AUTOSAR XML (schema 00046)
package /ComponentTypes
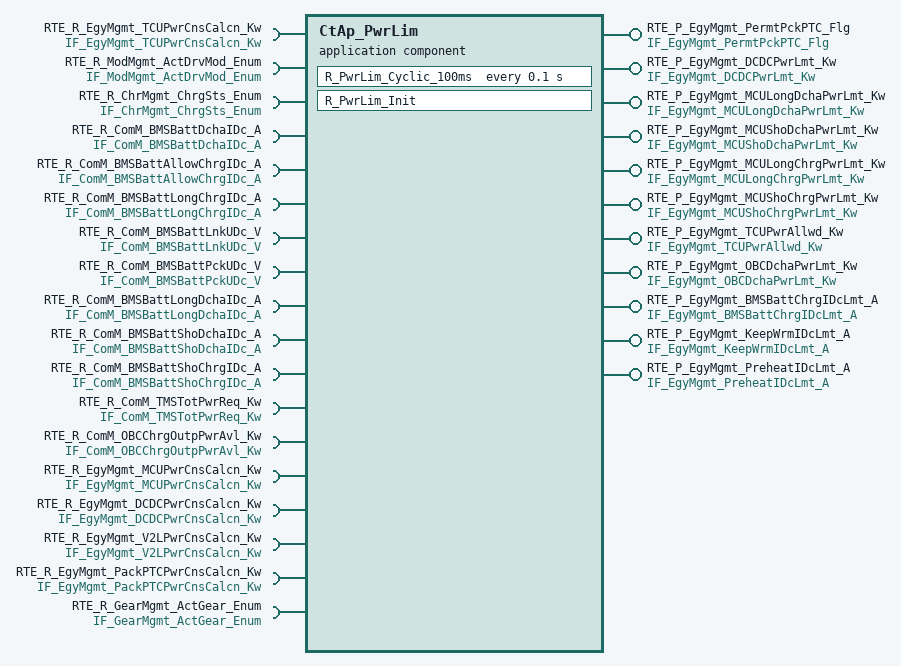
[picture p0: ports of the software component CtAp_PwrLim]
  application sw component type CtAp_PwrLim
    18 x require port:
      RTE_R_EgyMgmt_TCUPwrCnsCalcn_Kw: nonqueued-receiver-com-spec{data-element=tec_EgyMgmt_TCUPwrCnsCalcn_Kw, filter=data-filter-type=ALWAYS, init-value=0}, required-interface=IF_EgyMgmt_TCUPwrCnsCalcn_Kw
      RTE_R_ModMgmt_ActDrvMod_Enum: nonqueued-receiver-com-spec{data-element=tec_ModMgmt_ActDrvMod_Enum, filter=data-filter-type=ALWAYS, init-value=0}, required-interface=IF_ModMgmt_ActDrvMod_Enum
      RTE_R_ChrMgmt_ChrgSts_Enum: nonqueued-receiver-com-spec{data-element=tec_ChrMgmt_ChrgSts_Enum, filter=data-filter-type=ALWAYS, init-value=0}, required-interface=IF_ChrMgmt_ChrgSts_Enum
      RTE_R_ComM_BMSBattDchaIDc_A: nonqueued-receiver-com-spec{data-element=tec_ComM_BMSBattDchaIDc_A, filter=data-filter-type=ALWAYS, init-value=0}, required-interface=IF_ComM_BMSBattDchaIDc_A
      RTE_R_ComM_BMSBattAllowChrgIDc_A: nonqueued-receiver-com-spec{data-element=tec_ComM_BMSBattAllowChrgIDc_A, filter=data-filter-type=ALWAYS, init-value=0}, required-interface=IF_ComM_BMSBattAllowChrgIDc_A
      RTE_R_ComM_BMSBattLongChrgIDc_A: nonqueued-receiver-com-spec{data-element=tec_ComM_BMSBattLongChrgIDc_A, filter=data-filter-type=ALWAYS, init-value=0}, required-interface=IF_ComM_BMSBattLongChrgIDc_A
      RTE_R_ComM_BMSBattLnkUDc_V: nonqueued-receiver-com-spec{data-element=tec_ComM_BMSBattLnkUDc_V, filter=data-filter-type=ALWAYS, init-value=0}, required-interface=IF_ComM_BMSBattLnkUDc_V
      RTE_R_ComM_BMSBattPckUDc_V: nonqueued-receiver-com-spec{data-element=tec_ComM_BMSBattPckUDc_V, filter=data-filter-type=ALWAYS, init-value=0}, required-interface=IF_ComM_BMSBattPckUDc_V
      RTE_R_ComM_BMSBattLongDchaIDc_A: nonqueued-receiver-com-spec{data-element=tec_ComM_BMSBattLongDchaIDc_A, filter=data-filter-type=ALWAYS, init-value=0}, required-interface=IF_ComM_BMSBattLongDchaIDc_A
      RTE_R_ComM_BMSBattShoDchaIDc_A: nonqueued-receiver-com-spec{data-element=tec_ComM_BMSBattShoDchaIDc_A, filter=data-filter-type=ALWAYS, init-value=0}, required-interface=IF_ComM_BMSBattShoDchaIDc_A
      RTE_R_ComM_BMSBattShoChrgIDc_A: nonqueued-receiver-com-spec{data-element=tec_ComM_BMSBattShoChrgIDc_A, filter=data-filter-type=ALWAYS, init-value=0}, required-interface=IF_ComM_BMSBattShoChrgIDc_A
      RTE_R_ComM_TMSTotPwrReq_Kw: nonqueued-receiver-com-spec{data-element=tec_ComM_TMSTotPwrReq_Kw, filter=data-filter-type=ALWAYS, init-value=0}, required-interface=IF_ComM_TMSTotPwrReq_Kw
      RTE_R_ComM_OBCChrgOutpPwrAvl_Kw: nonqueued-receiver-com-spec{data-element=tec_ComM_OBCChrgOutpPwrAvl_Kw, filter=data-filter-type=ALWAYS, init-value=0}, required-interface=IF_ComM_OBCChrgOutpPwrAvl_Kw
      RTE_R_EgyMgmt_MCUPwrCnsCalcn_Kw: nonqueued-receiver-com-spec{data-element=tec_EgyMgmt_MCUPwrCnsCalcn_Kw, filter=data-filter-type=ALWAYS, init-value=0}, required-interface=IF_EgyMgmt_MCUPwrCnsCalcn_Kw
      RTE_R_EgyMgmt_DCDCPwrCnsCalcn_Kw: nonqueued-receiver-com-spec{data-element=tec_EgyMgmt_DCDCPwrCnsCalcn_Kw, filter=data-filter-type=ALWAYS, init-value=0}, required-interface=IF_EgyMgmt_DCDCPwrCnsCalcn_Kw
      RTE_R_EgyMgmt_V2LPwrCnsCalcn_Kw: nonqueued-receiver-com-spec{data-element=IF_EgyMgmt_V2LPwrCnsCalcn_Kw, filter=data-filter-type=ALWAYS, init-value=0}, required-interface=IF_EgyMgmt_V2LPwrCnsCalcn_Kw
      RTE_R_EgyMgmt_PackPTCPwrCnsCalcn_Kw: nonqueued-receiver-com-spec{data-element=tec_EgyMgmt_PackPTCPwrCnsCalcn_Kw, filter=data-filter-type=ALWAYS, init-value=0}, required-interface=IF_EgyMgmt_PackPTCPwrCnsCalcn_Kw
      RTE_R_GearMgmt_ActGear_Enum: nonqueued-receiver-com-spec{data-element=tec_GearMgmt_ActGear_Enum, filter=data-filter-type=ALWAYS, init-value=0}, required-interface=IF_GearMgmt_ActGear_Enum
    11 x provide port:
      RTE_P_EgyMgmt_PermtPckPTC_Flg: nonqueued-sender-com-spec{data-element=tec_EgyMgmt_PermtPckPTC_Flg, init-value=0}, provided-interface=IF_EgyMgmt_PermtPckPTC_Flg
      RTE_P_EgyMgmt_DCDCPwrLmt_Kw: nonqueued-sender-com-spec{data-element=tec_EgyMgmt_DCDCPwrLmt_Kw, init-value=0}, provided-interface=IF_EgyMgmt_DCDCPwrLmt_Kw
      RTE_P_EgyMgmt_MCULongDchaPwrLmt_Kw: nonqueued-sender-com-spec{data-element=tec_EgyMgmt_MCULongDchaPwrLmt_Kw, init-value=0}, provided-interface=IF_EgyMgmt_MCULongDchaPwrLmt_Kw
      RTE_P_EgyMgmt_MCUShoDchaPwrLmt_Kw: nonqueued-sender-com-spec{data-element=tec_EgyMgmt_MCUShoDchaPwrLmt_Kw, init-value=0}, provided-interface=IF_EgyMgmt_MCUShoDchaPwrLmt_Kw
      RTE_P_EgyMgmt_MCULongChrgPwrLmt_Kw: nonqueued-sender-com-spec{data-element=tec_EgyMgmt_MCULongChrgPwrLmt_Kw, init-value=0}, provided-interface=IF_EgyMgmt_MCULongChrgPwrLmt_Kw
      RTE_P_EgyMgmt_MCUShoChrgPwrLmt_Kw: nonqueued-sender-com-spec{data-element=tec_EgyMgmt_MCUShoChrgPwrLmt_Kw, init-value=0}, provided-interface=IF_EgyMgmt_MCUShoChrgPwrLmt_Kw
      RTE_P_EgyMgmt_TCUPwrAllwd_Kw: nonqueued-sender-com-spec{data-element=tec_EgyMgmt_TCUPwrAllwd_Kw, init-value=0}, provided-interface=IF_EgyMgmt_TCUPwrAllwd_Kw
      RTE_P_EgyMgmt_OBCDchaPwrLmt_Kw: nonqueued-sender-com-spec{data-element=tec_EgyMgmt_OBCDchaPwrLmt_Kw, init-value=0}, provided-interface=IF_EgyMgmt_OBCDchaPwrLmt_Kw
      RTE_P_EgyMgmt_BMSBattChrgIDcLmt_A: nonqueued-sender-com-spec{data-element=tec_EgyMgmt_BMSBattChrgIDcLmt_A, init-value=0}, provided-interface=IF_EgyMgmt_BMSBattChrgIDcLmt_A
      RTE_P_EgyMgmt_KeepWrmIDcLmt_A: nonqueued-sender-com-spec{data-element=tec_EgyMgmt_KeepWrmIDcLmt_A, init-value=0}, provided-interface=IF_EgyMgmt_KeepWrmIDcLmt_A
      RTE_P_EgyMgmt_PreheatIDcLmt_A: nonqueued-sender-com-spec{data-element=tec_EgyMgmt_PreheatIDcLmt_A, init-value=0}, provided-interface=IF_EgyMgmt_PreheatIDcLmt_A
    behavior CtAp_PwrLim_InternalBehavior
      init event CtAp_PwrLim_InitEvent: start-on-event=R_PwrLim_Init
      timing event TMT_R_PwrLim_Cyclic_100ms: start-on-event=R_PwrLim_Cyclic_100ms, period=0.1
      runnable R_PwrLim_Init
      runnable R_PwrLim_Cyclic_100ms
        data-receive-point-by-arguments:
          18 x access:
            REC_RTE_R_ChrMgmt_ChrgSts_Enum_tec_ChrMgmt_ChrgSts_Enum: accessed-variable=RTE_R_ChrMgmt_ChrgSts_Enum.tec_ChrMgmt_ChrgSts_Enum
            REC_RTE_R_ComM_BMSBattAllowChrgIDc_A_tec_ComM_BMSBattAllowChrgIDc_A: accessed-variable=RTE_R_ComM_BMSBattAllowChrgIDc_A.tec_ComM_BMSBattAllowChrgIDc_A
            REC_RTE_R_ComM_BMSBattDchaIDc_A_tec_ComM_BMSBattDchaIDc_A: accessed-variable=RTE_R_ComM_BMSBattDchaIDc_A.tec_ComM_BMSBattDchaIDc_A
            REC_RTE_R_ComM_BMSBattLnkUDc_V_tec_ComM_BMSBattLnkUDc_V: accessed-variable=RTE_R_ComM_BMSBattLnkUDc_V.tec_ComM_BMSBattLnkUDc_V
            REC_RTE_R_ComM_BMSBattLongChrgIDc_A_tec_ComM_BMSBattLongChrgIDc_A: accessed-variable=RTE_R_ComM_BMSBattLongChrgIDc_A.tec_ComM_BMSBattLongChrgIDc_A
            REC_RTE_R_ComM_BMSBattLongDchaIDc_A_tec_ComM_BMSBattLongDchaIDc_A: accessed-variable=RTE_R_ComM_BMSBattLongDchaIDc_A.tec_ComM_BMSBattLongDchaIDc_A
            REC_RTE_R_ComM_BMSBattPckUDc_V_tec_ComM_BMSBattPckUDc_V: accessed-variable=RTE_R_ComM_BMSBattPckUDc_V.tec_ComM_BMSBattPckUDc_V
            REC_RTE_R_ComM_BMSBattShoChrgIDc_A_tec_ComM_BMSBattShoChrgIDc_A: accessed-variable=RTE_R_ComM_BMSBattShoChrgIDc_A.tec_ComM_BMSBattShoChrgIDc_A
            REC_RTE_R_ComM_BMSBattShoDchaIDc_A_tec_ComM_BMSBattShoDchaIDc_A: accessed-variable=RTE_R_ComM_BMSBattShoDchaIDc_A.tec_ComM_BMSBattShoDchaIDc_A
            REC_RTE_R_ComM_OBCChrgOutpPwrAvl_Kw_tec_ComM_OBCChrgOutpPwrAvl_Kw: accessed-variable=RTE_R_ComM_OBCChrgOutpPwrAvl_Kw.tec_ComM_OBCChrgOutpPwrAvl_Kw
            REC_RTE_R_ComM_TMSTotPwrReq_Kw_tec_ComM_TMSTotPwrReq_Kw: accessed-variable=RTE_R_ComM_TMSTotPwrReq_Kw.tec_ComM_TMSTotPwrReq_Kw
            REC_RTE_R_EgyMgmt_DCDCPwrCnsCalcn_Kw_tec_EgyMgmt_DCDCPwrCnsCalcn_Kw: accessed-variable=RTE_R_EgyMgmt_DCDCPwrCnsCalcn_Kw.tec_EgyMgmt_DCDCPwrCnsCalcn_Kw
            REC_RTE_R_EgyMgmt_MCUPwrCnsCalcn_Kw_tec_EgyMgmt_MCUPwrCnsCalcn_Kw: accessed-variable=RTE_R_EgyMgmt_MCUPwrCnsCalcn_Kw.tec_EgyMgmt_MCUPwrCnsCalcn_Kw
            REC_RTE_R_EgyMgmt_PackPTCPwrCnsCalcn_Kw_tec_EgyMgmt_PackPTCPwrCnsCalcn_Kw: accessed-variable=RTE_R_EgyMgmt_PackPTCPwrCnsCalcn_Kw.tec_EgyMgmt_PackPTCPwrCnsCalcn_Kw
            REC_RTE_R_EgyMgmt_TCUPwrCnsCalcn_Kw_tec_EgyMgmt_TCUPwrCnsCalcn_Kw: accessed-variable=RTE_R_EgyMgmt_TCUPwrCnsCalcn_Kw.tec_EgyMgmt_TCUPwrCnsCalcn_Kw
            REC_RTE_R_EgyMgmt_V2LPwrCnsCalcn_Kw_IF_EgyMgmt_V2LPwrCnsCalcn_Kw: accessed-variable=RTE_R_EgyMgmt_V2LPwrCnsCalcn_Kw.IF_EgyMgmt_V2LPwrCnsCalcn_Kw
            REC_RTE_R_GearMgmt_ActGear_Enum_tec_GearMgmt_ActGear_Enum: accessed-variable=RTE_R_GearMgmt_ActGear_Enum.tec_GearMgmt_ActGear_Enum
            REC_RTE_R_ModMgmt_ActDrvMod_Enum_tec_ModMgmt_ActDrvMod_Enum: accessed-variable=RTE_R_ModMgmt_ActDrvMod_Enum.tec_ModMgmt_ActDrvMod_Enum
        data-send-points:
          11 x access:
            SEND_RTE_P_EgyMgmt_BMSBattChrgIDcLmt_A_tec_EgyMgmt_BMSBattChrgIDcLmt_A: accessed-variable=RTE_P_EgyMgmt_BMSBattChrgIDcLmt_A.tec_EgyMgmt_BMSBattChrgIDcLmt_A
            SEND_RTE_P_EgyMgmt_DCDCPwrLmt_Kw_tec_EgyMgmt_DCDCPwrLmt_Kw: accessed-variable=RTE_P_EgyMgmt_DCDCPwrLmt_Kw.tec_EgyMgmt_DCDCPwrLmt_Kw
            SEND_RTE_P_EgyMgmt_KeepWrmIDcLmt_A_tec_EgyMgmt_KeepWrmIDcLmt_A: accessed-variable=RTE_P_EgyMgmt_KeepWrmIDcLmt_A.tec_EgyMgmt_KeepWrmIDcLmt_A
            SEND_RTE_P_EgyMgmt_MCULongChrgPwrLmt_Kw_tec_EgyMgmt_MCULongChrgPwrLmt_Kw: accessed-variable=RTE_P_EgyMgmt_MCULongChrgPwrLmt_Kw.tec_EgyMgmt_MCULongChrgPwrLmt_Kw
            SEND_RTE_P_EgyMgmt_MCULongDchaPwrLmt_Kw_tec_EgyMgmt_MCULongDchaPwrLmt_Kw: accessed-variable=RTE_P_EgyMgmt_MCULongDchaPwrLmt_Kw.tec_EgyMgmt_MCULongDchaPwrLmt_Kw
            SEND_RTE_P_EgyMgmt_MCUShoChrgPwrLmt_Kw_tec_EgyMgmt_MCUShoChrgPwrLmt_Kw: accessed-variable=RTE_P_EgyMgmt_MCUShoChrgPwrLmt_Kw.tec_EgyMgmt_MCUShoChrgPwrLmt_Kw
            SEND_RTE_P_EgyMgmt_MCUShoDchaPwrLmt_Kw_tec_EgyMgmt_MCUShoDchaPwrLmt_Kw: accessed-variable=RTE_P_EgyMgmt_MCUShoDchaPwrLmt_Kw.tec_EgyMgmt_MCUShoDchaPwrLmt_Kw
            SEND_RTE_P_EgyMgmt_OBCDchaPwrLmt_Kw_tec_EgyMgmt_OBCDchaPwrLmt_Kw: accessed-variable=RTE_P_EgyMgmt_OBCDchaPwrLmt_Kw.tec_EgyMgmt_OBCDchaPwrLmt_Kw
            SEND_RTE_P_EgyMgmt_PermtPckPTC_Flg_tec_EgyMgmt_PermtPckPTC_Flg: accessed-variable=RTE_P_EgyMgmt_PermtPckPTC_Flg.tec_EgyMgmt_PermtPckPTC_Flg
            SEND_RTE_P_EgyMgmt_PreheatIDcLmt_A_tec_EgyMgmt_PreheatIDcLmt_A: accessed-variable=RTE_P_EgyMgmt_PreheatIDcLmt_A.tec_EgyMgmt_PreheatIDcLmt_A
            SEND_RTE_P_EgyMgmt_TCUPwrAllwd_Kw_tec_EgyMgmt_TCUPwrAllwd_Kw: accessed-variable=RTE_P_EgyMgmt_TCUPwrAllwd_Kw.tec_EgyMgmt_TCUPwrAllwd_Kw
  swc implementation CtAp_PwrLim_Implementation: behavior=CtAp_PwrLim_InternalBehavior
    code-descriptors:
      code Default: artifact-descriptors=autosar-engineering-object=category=SWOBJ
